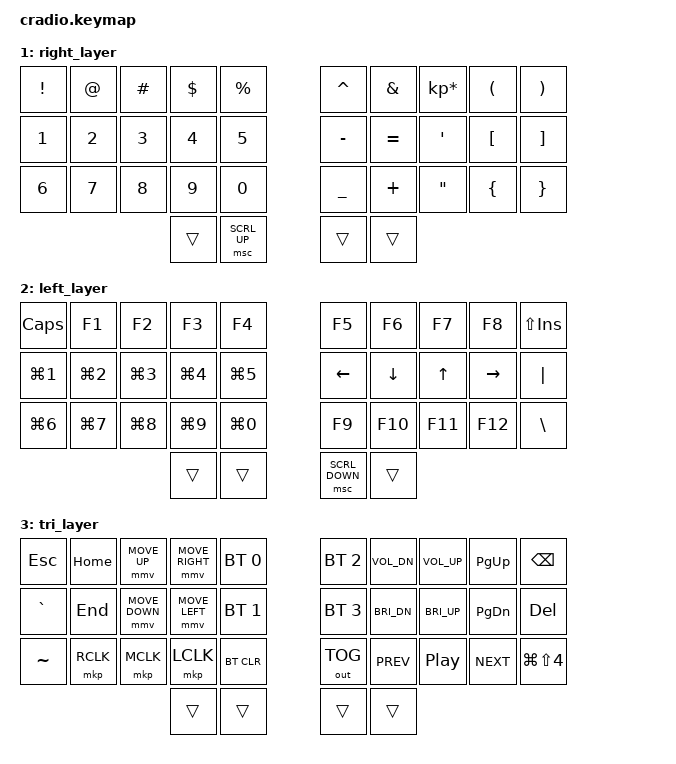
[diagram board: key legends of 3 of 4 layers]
// Copyright (c) 2022 The ZMK Contributors
// SPDX-License-Identifier: MIT

#include <behaviors.dtsi>
#include <dt-bindings/zmk/keys.h>
#include <dt-bindings/zmk/bt.h>
#include <dt-bindings/zmk/outputs.h>
#include <dt-bindings/zmk/pointing.h>

// Home row mods macro
#define HRML(k1,k2,k3,k4) &ht LCTRL k1  &ht LALT k2  &ht LSHFT k3  &ht LGUI k4
#define HRMR(k1,k2,k3,k4) &ht RGUI k1  &ht LSHFT k2  &ht RALT k3  &ht RCTRL k4

/ {
	behaviors {
		ht: hold_tap {
			label = "hold_tap";
			compatible = "zmk,behavior-hold-tap";
			#binding-cells = <2>;
			flavor = "tap-preferred";
			tapping-term-ms = <220>;
			quick-tap-ms = <120>;
			require-prior-idle-ms = <100>;
			//global-quick-tap;
			bindings = <&kp>, <&kp>;
			//quick-tap-ms = <0>;
			//require-prior-idle-ms = <150>;
		};
	};

    conditional_layers {
        compatible = "zmk,conditional-layers";
        tri_layer {
            if-layers = <1 2>;
            then-layer = <3>;
        };
    };

    keymap {
        compatible = "zmk,keymap";
        default_layer {
            bindings = <
        //╭──────────┬──────────┬──────────┬──────────┬──────────╮   ╭──────────┬──────────┬──────────┬──────────┬──────────╮
        //│  Q       │  W       │  E       │  R       │  T       │   │  Y       │  U       │  I       │  O       │  P       │
            &kp Q      &kp W      &kp E      &kp R      &kp T          &kp Y      &kp U      &kp I      &kp O      &kp P
        //├──────────┼──────────┼──────────┼──────────┼──────────┤   ├──────────┼──────────┼──────────┼──────────┼──────────┤
        //│  A       │  S       │  D       │  F       │  G       │   │  H       │  J       │  K       │  L       │ ' "      │
            HRML(A,        S,         D,         F)     &kp G          &kp H      HRMR(J,        K,         L,        SEMI)
        //├──────────┼──────────┼──────────┼──────────┼──────────┤   ├──────────┼──────────┼──────────┼──────────┼──────────┤
        //│  Z       │  X       │  C       │  V       │  B       │   │  N       │  M       │ , <      │ . >      │ / ?      │
            &kp Z      &kp X      &kp C      &kp V      &kp B          &kp N      &kp M      &kp COMMA  &kp DOT    &kp FSLH
        //╰──────────┴──────────┴──────────┼──────────┼──────────┤   ├──────────┼──────────┼──────────┴──────────┴──────────╯
                                            &lt 2 TAB   &ht LGUI SPACE     &kp ENTER  &lt 1 BSPC
        //                                 ╰──────────┴──────────╯   ╰──────────┴──────────╯
            >;
        };

        right_layer {
            bindings = <
        //╭──────────┬──────────┬──────────┬──────────┬──────────╮   ╭──────────┬──────────┬──────────┬──────────┬──────────╮
        //│ INSERT   │  1       │  2       │  3       │          │   │ HOME     │ PAGE DN  │ PAGE UP  │ END      │  :       │
            &kp EXCL &kp AT &kp HASH &kp DLLR &kp PRCNT                &kp CARET &kp AMPS  &kp KP_MULTIPLY &kp LPAR &kp RPAR 
        //├──────────┼──────────┼──────────┼──────────┼──────────┤   ├──────────┼──────────┼──────────┼──────────┼──────────┤
        //│ DELETE   │  4       │  5       │  6       │          │   │ LEFT     │ DOWN     │ UP       │ RIGHT    │  ;       │
            &kp N1 &kp N2 &kp N3 &kp N4 &kp N5						             &kp MINUS &kp EQUAL &kp SQT &kp LBKT &kp RBKT 
        //├──────────┼──────────┼──────────┼──────────┼──────────┤   ├──────────┼──────────┼──────────┼──────────┼──────────┤
        //│ CAPS     │  7       │  8       │  9       │  0       │   │          │          │          │          │          │
            &kp N6 &kp N7 &kp N8 &kp N9 &kp N0						             &kp UNDER &kp PLUS  &kp DQT &kp LBRC &kp RBRC
        //╰──────────┴──────────┴──────────┼──────────┼──────────┤   ├──────────┼──────────┼──────────┴──────────┴──────────╯
                                 &trans     &msc SCRL_UP              &trans     &trans
        //                                 ╰──────────┴──────────╯   ╰──────────┴──────────╯
            >;
        };

        left_layer {
            bindings = <
        //╭──────────┬──────────┬──────────┬──────────┬──────────╮   ╭──────────┬──────────┬──────────┬──────────┬──────────╮
        //│          │  [       │  {       │  }       │          │   │  ^       │  (       │  )       │  ]       │  ~       │
            &kp CAPS &kp F1 &kp F2 &kp F3 &kp F4                        &kp F5 &kp F6 &kp F7 &kp F8  &kp LS(INS) 
        //├──────────┼──────────┼──────────┼──────────┼──────────┤   ├──────────┼──────────┼──────────┼──────────┼──────────┤
        //│  !       │  @       │  #       │  $       │  %       │   │  *       │  -       │  =       │  \       │  `       │
            &kp LG(N1) &kp LG(N2) &kp LG(N3) &kp LG(N4) &kp LG(N5)      &kp LEFT &kp DOWN &kp UP &kp RIGHT &kp PIPE 
        //├──────────┼──────────┼──────────┼──────────┼──────────┤   ├──────────┼──────────┼──────────┼──────────┼──────────┤
        //│          │          │          │          │          │   │  &       │  _       │  +       │  │       │          │
            &kp LG(N6) &kp LG(N7) &kp LG(N8) &kp LG(N9) &kp LG(N0)      &kp F9 &kp F10 &kp F11 &kp F12 &kp BSLH 
        //╰──────────┴──────────┴──────────┼──────────┼──────────┤   ├──────────┼──────────┼──────────┴──────────┴──────────╯
                                                 &trans     &trans      &msc SCRL_DOWN &trans
        //                                 ╰──────────┴──────────╯   ╰──────────┴──────────╯
            >;
        };

        tri_layer {
            bindings = <
        //╭──────────┬──────────┬──────────┬──────────┬──────────╮   ╭──────────┬──────────┬──────────┬──────────┬──────────╮
        //│ RESET    │          │          │          │PROFILE 0 │   │PROFILE 2 │VOL DN    │VOL UP    │ PG UP    │   BSPC   │
           &kp ESC &kp HOME &mmv MOVE_UP &mmv MOVE_RIGHT &bt BT_SEL 0   &bt BT_SEL 2 &kp C_VOL_DN &kp C_VOL_UP &kp PG_UP &kp BSPC
        //├──────────┼──────────┼──────────┼──────────┼──────────┤   ├──────────┼──────────┼──────────┼──────────┼──────────┤
        //│BOOTLOADER│          │          │          │PROFILE 1 │   │ PROFILE 3│DEC BRIGHT│INC BRIGHT│ PG DN    │   DEL    │
           &kp GRAVE  &kp END &mmv MOVE_DOWN &mmv MOVE_LEFT &bt BT_SEL 1   &bt BT_SEL 3 &kp C_BRI_DN &kp C_BRI_UP &kp PG_DN &kp DEL
        //├──────────┼──────────┼──────────┼──────────┼──────────┤   ├──────────┼──────────┼──────────┼──────────┼──────────┤
        //│          │          │          │          │CLEAR BT  │   |SWITCH_OUT│ PREVSONG │PAUSEMUSIC│ NEXTSONG │          │
           &kp TILDE  &mkp RCLK  &mkp MCLK  &mkp LCLK  &bt BT_CLR     &out OUT_TOG &kp C_PREV &kp C_PP &kp C_NEXT &kp LG(LS(N4))
        //╰──────────┴──────────┴──────────┼──────────┼──────────┤   ├──────────┼──────────┼──────────┴──────────┴──────────╯
                                           &trans     &trans         &trans     &trans
        //                                 ╰──────────┴──────────╯   ╰──────────┴──────────╯
            >;
        };
    };
};
